AUTOSAR XML (schema 4-0-3)
package /ComponentTypes
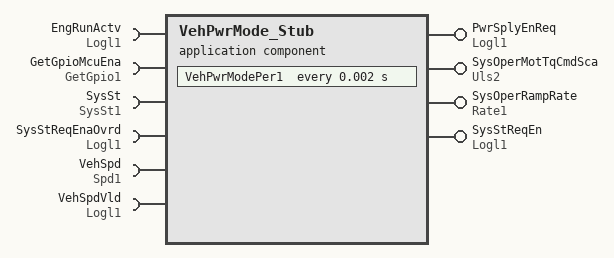
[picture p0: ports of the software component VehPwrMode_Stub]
  application sw component type VehPwrMode_Stub
    4 x provide port:
      PwrSplyEnReq: nonqueued-sender-com-spec{data-element=Logl, init-value=0}, provided-interface=Logl1
      SysOperMotTqCmdSca: nonqueued-sender-com-spec{data-element=Val, init-value=0}, provided-interface=Uls2
      SysOperRampRate: nonqueued-sender-com-spec{data-element=Val, init-value=0}, provided-interface=Rate1
      SysStReqEn: nonqueued-sender-com-spec{data-element=Logl, init-value=0}, provided-interface=Logl1
    6 x require port:
      EngRunActv: nonqueued-receiver-com-spec{data-element=Logl, filter=data-filter-type=ALWAYS, init-value=0}, required-interface=Logl1
      GetGpioMcuEna: required-interface=GetGpio1
      SysSt: nonqueued-receiver-com-spec{data-element=Val, filter=data-filter-type=ALWAYS, init-value=3}, required-interface=SysSt1
      SysStReqEnaOvrd: nonqueued-receiver-com-spec{data-element=Logl, filter=data-filter-type=ALWAYS, init-value=0}, required-interface=Logl1
      VehSpd: nonqueued-receiver-com-spec{data-element=Val, filter=data-filter-type=ALWAYS, init-value=0}, required-interface=Spd1
      VehSpdVld: nonqueued-receiver-com-spec{data-element=Logl, filter=data-filter-type=ALWAYS, init-value=0}, required-interface=Logl1
    behavior VehPwrMode_Stub_InternalBehavior: data-type-mapping=Nexteer
      timing event TMT_VehPwrModePer1: start-on-event=VehPwrModePer1, period=0.002
      runnable VehPwrModePer1
        data-receive-point-by-arguments:
          5 x access:
            REC_EngRunActv_Logl: accessed-variable=EngRunActv.Logl
            REC_SysSt_Val: accessed-variable=SysSt.Val
            REC_SysStReqEnaOvrd_Logl: accessed-variable=SysStReqEnaOvrd.Logl
            REC_VehSpd_Val: accessed-variable=VehSpd.Val
            REC_VehSpdVld_Logl: accessed-variable=VehSpdVld.Logl
        data-send-points:
          4 x access:
            SEND_PwrSplyEnReq_Logl: accessed-variable=PwrSplyEnReq.Logl
            SEND_SysOperMotTqCmdSca_Val: accessed-variable=SysOperMotTqCmdSca.Val
            SEND_SysOperRampRate_Val: accessed-variable=SysOperRampRate.Val
            SEND_SysStReqEn_Logl: accessed-variable=SysStReqEn.Logl
        sync call SC_GetGpioMcuEna_Oper: operation=GetGpioMcuEna.Oper, timeout=0
  swc implementation VehPwrMode_Stub_Implementation: behavior=VehPwrMode_Stub_InternalBehavior
    code-descriptors:
      code Default: artifact-descriptors=autosar-engineering-object={short-label=Default, category=SWSRC}
